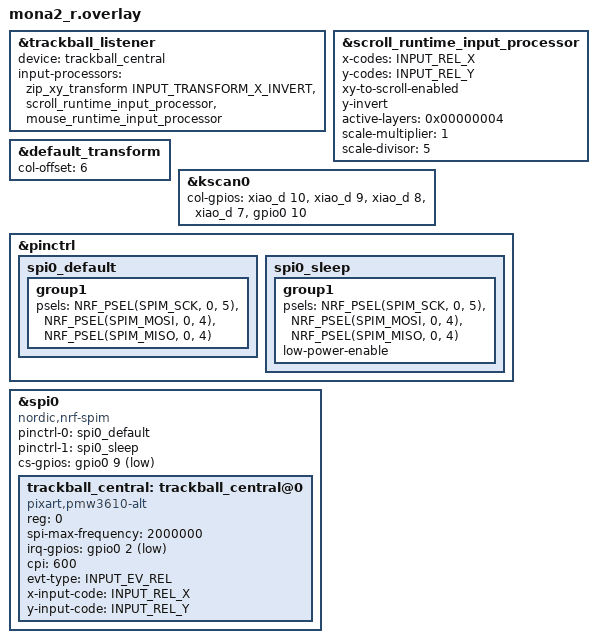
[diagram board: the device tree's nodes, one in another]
#include "mona2.dtsi"
#include <input/processors/runtime-input-processor.dtsi>
#include <zephyr/dt-bindings/input/input-event-codes.h>

&trackball_listener {
    status = "okay";
    device = <&trackball_central>;
    
    /* 軸反転はここで統一管理（Kconfig の PMW3610_ALT_INVERT_X/Y は使用しない）
     * scroll を mouse より先に置く。scroll が対象レイヤーで REL_X/Y を WHEEL に
     * 変換するため、mouse の感度設定がスクロール量に掛からない。
     */
    input-processors =
        <&zip_xy_transform INPUT_TRANSFORM_X_INVERT>,
        <&scroll_runtime_input_processor>,
        <&mouse_runtime_input_processor>;
};

/* スクロールの対象レイヤーと速度の初期値。DYA Studio から変更できる。
 * active-layers はレイヤー番号のビットマスク（0x4 = Layer 2）。
 */
&scroll_runtime_input_processor {
    x-codes = <INPUT_REL_X>;
    y-codes = <INPUT_REL_Y>;
    xy-to-scroll-enabled;
    y-invert;
    active-layers = <0x00000004>;
    scale-multiplier = <1>;
    scale-divisor = <5>;
};

&default_transform {
    col-offset = <6>;
};

&kscan0 {
    col-gpios
        = <&xiao_d 10 GPIO_ACTIVE_HIGH>
        , <&xiao_d 9 GPIO_ACTIVE_HIGH> 
        , <&xiao_d 8 GPIO_ACTIVE_HIGH> 
        , <&xiao_d 7 GPIO_ACTIVE_HIGH> 
        , <&gpio0 10 GPIO_ACTIVE_HIGH>
        ;
};

/* 半二重 SPI: PMW3610 の SDIO ライン用に MOSI/MISO を同一ピン (P0.04) に割り当て。
 * この SPI バスに他のデバイスを追加しないこと。
 */
&pinctrl {
    spi0_default: spi0_default {
        group1 {
            psels = <NRF_PSEL(SPIM_SCK, 0, 5)>,
                <NRF_PSEL(SPIM_MOSI, 0, 4)>,
                <NRF_PSEL(SPIM_MISO, 0, 4)>;
        };
    };

    spi0_sleep: spi0_sleep {
        group1 {
            psels = <NRF_PSEL(SPIM_SCK, 0, 5)>,
                <NRF_PSEL(SPIM_MOSI, 0, 4)>,
                <NRF_PSEL(SPIM_MISO, 0, 4)>;
            low-power-enable;
        };
    };
};

&spi0 {
    status = "okay";
    compatible = "nordic,nrf-spim";
    pinctrl-0 = <&spi0_default>;
    pinctrl-1 = <&spi0_sleep>;
    pinctrl-names = "default", "sleep";
    cs-gpios = <&gpio0 9 GPIO_ACTIVE_LOW>;

    trackball_central: trackball_central@0 {
        status = "okay";
        compatible = "pixart,pmw3610-alt";
        reg = <0>;
        spi-max-frequency = <2000000>;
        irq-gpios = <&gpio0 2 (GPIO_ACTIVE_LOW | GPIO_PULL_UP)>;
        cpi = <600>;
        evt-type = <INPUT_EV_REL>;
        x-input-code = <INPUT_REL_X>;
        y-input-code = <INPUT_REL_Y>;
    };
};
